VERSION ""

NS_ :

BS_:

BU_: K16_BECM K73_TCIC K9_BCM K43_PSCM K17_EBCM K20_ECM K114B_HPCM NEO K124_ASCM EPB INTERCEPTOR XXX Vector__XXX

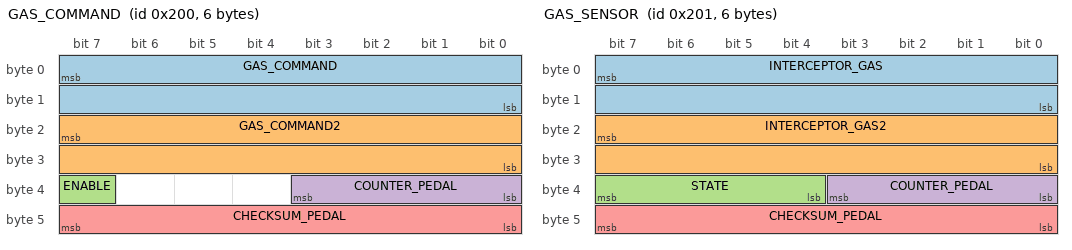
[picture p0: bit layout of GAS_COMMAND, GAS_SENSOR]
BO_ 512 GAS_COMMAND: 6 NEO
 SG_ GAS_COMMAND : 7|16@0+ (0.125677,-75.909) [0|1] "" INTERCEPTOR
 SG_ GAS_COMMAND2 : 23|16@0+ (0.251976,-76.601) [0|1] "" INTERCEPTOR
 SG_ ENABLE : 39|1@0+ (1,0) [0|1] "" INTERCEPTOR
 SG_ COUNTER_PEDAL : 35|4@0+ (1,0) [0|15] "" INTERCEPTOR
 SG_ CHECKSUM_PEDAL : 47|8@0+ (1,0) [0|255] "" INTERCEPTOR

BO_ 513 GAS_SENSOR: 6 INTERCEPTOR
 SG_ INTERCEPTOR_GAS : 7|16@0+ (0.125677,-75.909) [0|1] "" NEO
 SG_ INTERCEPTOR_GAS2 : 23|16@0+ (0.251976,-76.601) [0|1] "" NEO
 SG_ STATE : 39|4@0+ (1,0) [0|15] "" NEO
 SG_ COUNTER_PEDAL : 35|4@0+ (1,0) [0|15] "" NEO
 SG_ CHECKSUM_PEDAL : 47|8@0+ (1,0) [0|255] "" NEO

BO_ 189 EBCMRegenPaddle: 7 K17_EBCM
 SG_ RegenPaddle : 7|4@0+ (1,0) [0|0] "" NEO

BO_ 190 ECMAcceleratorPos: 6 K20_ECM
 SG_ BrakePedalPos : 15|8@0+ (1,0) [0|0] "sticky" NEO
 SG_ GasPedalAndAcc : 23|8@0+ (1,0) [0|0] "" NEO

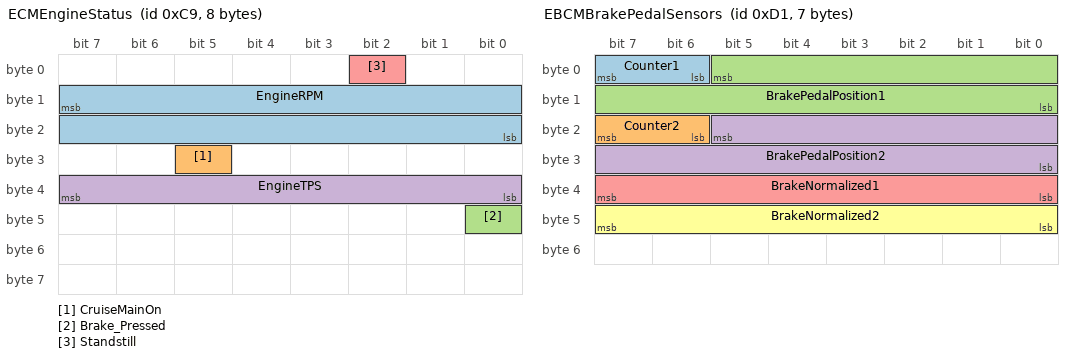
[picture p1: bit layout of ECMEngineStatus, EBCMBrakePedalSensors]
BO_ 201 ECMEngineStatus: 8 K20_ECM
 SG_ EngineRPM : 15|16@0+ (0.25,0) [0|0] "RPM" NEO
 SG_ CruiseMainOn : 29|1@0+ (1,0) [0|1] "" NEO
 SG_ Brake_Pressed : 40|1@0+ (1,0) [0|1] "" NEO
 SG_ EngineTPS : 39|8@0+ (0.392156863,0) [0|100.000000065] "%" NEO
 SG_ Standstill : 2|1@0+ (1,0) [0|1] "" NEO

BO_ 209 EBCMBrakePedalSensors: 7 K17_EBCM
 SG_ Counter1 : 7|2@0+ (1,0) [0|3] "" XXX
 SG_ Counter2 : 23|2@0+ (1,0) [0|3] "" XXX
 SG_ BrakePedalPosition1 : 5|14@0+ (1,0) [0|16383] "" XXX
 SG_ BrakePedalPosition2 : 21|14@0- (-1,0) [0|16383] "" XXX
 SG_ BrakeNormalized1 : 39|8@0+ (1,0) [0|255] "" XXX
 SG_ BrakeNormalized2 : 47|8@0- (-1,0) [0|255] "" XXX

BO_ 241 EBCMBrakePedalPosition: 6 K17_EBCM
 SG_ BrakePedalPosition : 15|8@0+ (1,0) [0|255] "" NEO

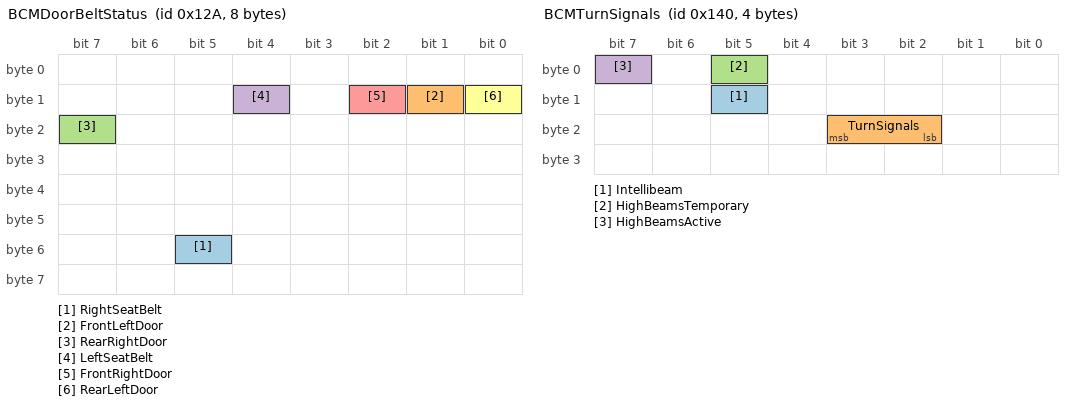
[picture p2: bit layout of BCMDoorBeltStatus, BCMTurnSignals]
BO_ 298 BCMDoorBeltStatus: 8 K9_BCM
 SG_ RightSeatBelt : 53|1@0+ (1,0) [0|0] "" NEO
 SG_ FrontLeftDoor : 9|1@0+ (1,0) [0|0] "" NEO
 SG_ RearRightDoor : 23|1@0+ (1,0) [0|0] "" NEO
 SG_ LeftSeatBelt : 12|1@0+ (1,0) [0|0] "" NEO
 SG_ FrontRightDoor : 10|1@0+ (1,0) [0|0] "" NEO
 SG_ RearLeftDoor : 8|1@0+ (1,0) [0|0] "" NEO

BO_ 309 ECMPRDNL: 8 K20_ECM
 SG_ PRNDL : 2|3@0+ (1,0) [0|0] "" NEO
 SG_ ESPButton : 4|1@0+ (1,0) [0|1] "" XXX

BO_ 320 BCMTurnSignals: 4 K9_BCM
 SG_ Intellibeam : 13|1@0+ (1,0) [0|1] "" XXX
 SG_ TurnSignals : 19|2@0+ (1,0) [0|0] "" NEO
 SG_ HighBeamsTemporary : 5|1@0+ (1,0) [0|1] "" XXX
 SG_ HighBeamsActive : 7|1@0+ (1,0) [0|1] "" XXX

BO_ 328 PSCM_148: 1 K43_PSCM

BO_ 381 ESPStatus: 8 K20_ECM
 SG_ TractionControlOn : 5|1@0+ (1,0) [0|0] "" NEO
 SG_ MSG17D_AccPower : 35|12@0- (1,0) [0|0] "" NEO

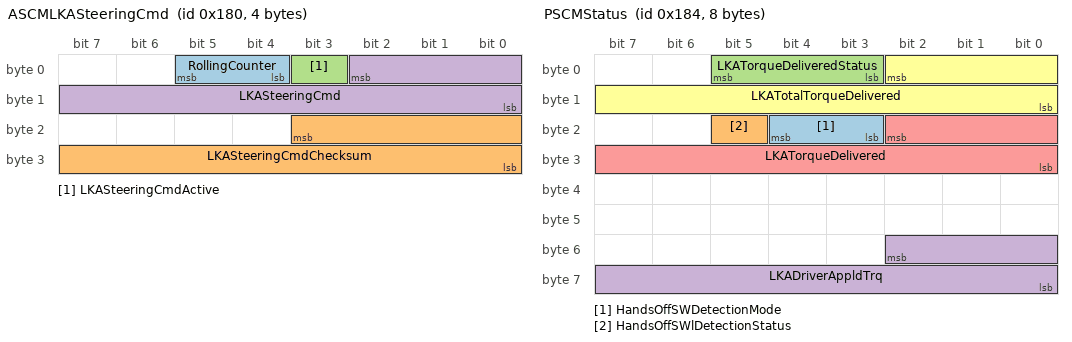
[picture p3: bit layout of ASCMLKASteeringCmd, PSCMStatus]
BO_ 384 ASCMLKASteeringCmd: 4 NEO
 SG_ RollingCounter : 5|2@0+ (1,0) [0|0] "" NEO
 SG_ LKASteeringCmdChecksum : 19|12@0+ (1,0) [0|0] "" NEO
 SG_ LKASteeringCmdActive : 3|1@0+ (1,0) [0|0] "" NEO
 SG_ LKASteeringCmd : 2|11@0- (1,0) [0|0] "" NEO

BO_ 388 PSCMStatus: 8 K43_PSCM
 SG_ HandsOffSWDetectionMode : 20|2@0+ (1,0) [0|3] "" NEO
 SG_ HandsOffSWlDetectionStatus : 21|1@0+ (1,0) [0|1] "" NEO
 SG_ LKATorqueDeliveredStatus : 5|3@0+ (1,0) [0|7] "" NEO
 SG_ LKADriverAppldTrq : 50|11@0- (0.01,0) [-10.24|10.23] "Nm" NEO
 SG_ LKATorqueDelivered : 18|11@0- (0.01,0) [0|1] "" NEO
 SG_ LKATotalTorqueDelivered : 2|11@0- (0.01,0) [-10.24|10.23] "Nm" NEO

BO_ 417 AcceleratorPedal: 7 XXX
 SG_ AcceleratorPedal : 55|8@0+ (1,0) [0|0] "" NEO

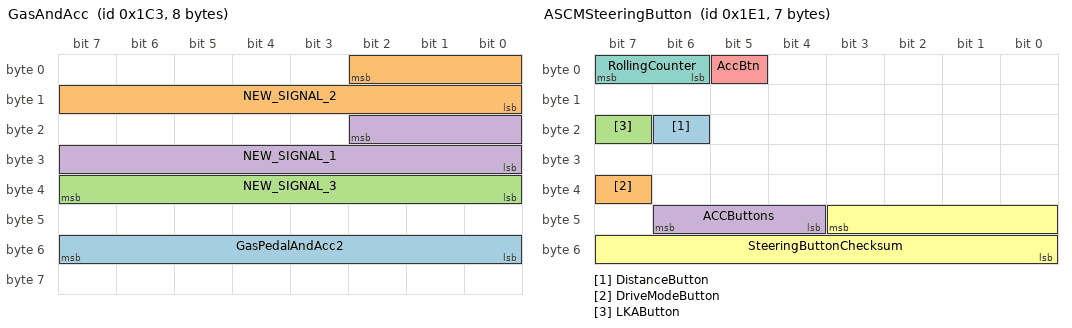
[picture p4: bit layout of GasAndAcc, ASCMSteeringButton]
BO_ 451 GasAndAcc: 8 XXX
 SG_ GasPedalAndAcc2 : 55|8@0+ (1,0) [0|0] "" NEO
 SG_ NEW_SIGNAL_2 : 2|11@0+ (1,0) [0|2047] "" XXX
 SG_ NEW_SIGNAL_3 : 32|8@1+ (1,0) [0|255] "" XXX
 SG_ NEW_SIGNAL_1 : 18|11@0+ (1,0) [0|2047] "" XXX

BO_ 452 AcceleratorPedal2: 8 XXX
 SG_ CruiseState : 15|3@0+ (1,0) [0|7] "" NEO
 SG_ AcceleratorPedal2 : 47|8@0+ (1,0) [0|0] "" NEO

BO_ 481 ASCMSteeringButton: 7 K124_ASCM
 SG_ DistanceButton : 22|1@0+ (1,0) [0|0] "" NEO
 SG_ DriveModeButton : 39|1@0+ (1,0) [0|1] "" XXX
 SG_ LKAButton : 23|1@0+ (1,0) [0|0] "" NEO
 SG_ ACCButtons : 46|3@0+ (1,0) [0|0] "" NEO
 SG_ AccBtn : 5|1@0+ (1,0) [0|1] "" XXX
 SG_ SteeringButtonChecksum : 43|12@0+ (1,0) [0|255] "" NEO
 SG_ RollingCounter : 7|2@0+ (1,0) [0|3] "" NEO

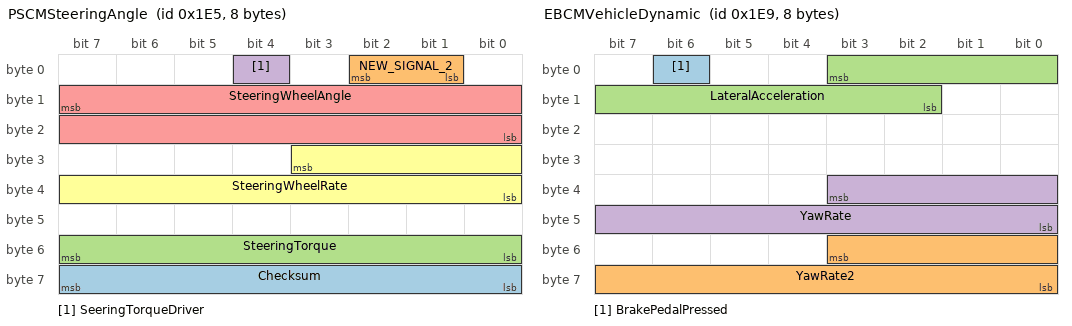
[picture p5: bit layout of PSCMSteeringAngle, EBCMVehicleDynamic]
BO_ 485 PSCMSteeringAngle: 8 K43_PSCM
 SG_ Checksum : 56|8@1+ (1,0) [0|255] "" XXX
 SG_ NEW_SIGNAL_2 : 1|2@1+ (1,0) [0|255] "" XXX
 SG_ SteeringTorque : 48|8@1- (1,0) [-2047|2047] "" XXX
 SG_ SeeringTorqueDriver : 4|1@1- (1,0) [-255|255] "" XXX
 SG_ SteeringWheelAngle : 15|16@0- (0.0625,0) [-2047|2047] "deg" NEO
 SG_ SteeringWheelRate : 27|12@0- (1,0) [-2047|2047] "deg/s" NEO

BO_ 489 EBCMVehicleDynamic: 8 K17_EBCM
 SG_ BrakePedalPressed : 6|1@0+ (1,0) [0|0] "" NEO
 SG_ YawRate2 : 51|12@0- (0.0625,0) [-2047|2047] "grad/s" NEO
 SG_ LateralAcceleration : 3|10@0- (1,0) [-2047|2047] "m/s2" NEO
 SG_ YawRate : 35|12@0- (1,0) [0|1] "" NEO

BO_ 352 VehicleIgnition: 5 XXX
 SG_ Ignition : 7|32@0+ (1,0) [0|4294967295] "" XXX

BO_ 497 VehicleIgnitionAlt: 8 XXX
 SG_ Ignition : 5|1@0+ (1,0) [0|1] "" XXX
 SG_ ParkBrake : 36|1@0+ (1,0) [0|3] "" XXX

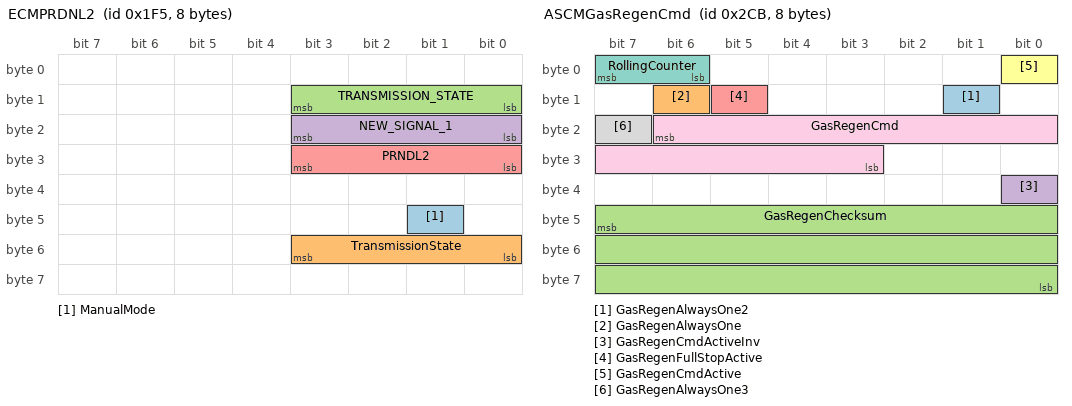
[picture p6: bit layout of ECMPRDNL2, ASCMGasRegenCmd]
BO_ 501 ECMPRDNL2: 8 K20_ECM
 SG_ ManualMode : 41|1@0+ (1,0) [0|1] "" NEO
 SG_ TransmissionState : 48|4@1+ (1,0) [0|7] "" NEO
 SG_ TRANSMISSION_STATE : 8|4@1+ (1,0) [0|15] "" XXX
 SG_ NEW_SIGNAL_1 : 16|4@1+ (1,0) [0|15] "" XXX
 SG_ PRNDL2 : 27|4@0+ (1,0) [0|255] "" NEO

BO_ 560 EPBStatus: 8 EPB
 SG_ EPBClosed : 12|1@0+ (1,0) [0|1] "" NEO

BO_ 711 BECMBatteryVoltageCurrent: 6 K17_EBCM
 SG_ HVBatteryVoltage : 31|12@0+ (0.125,0) [0|511.875] "V" NEO
 SG_ HVBatteryCurrent : 12|13@0- (0.15,0) [-614.4|614.25] "A" NEO

BO_ 715 ASCMGasRegenCmd: 8 K124_ASCM
 SG_ GasRegenAlwaysOne2 : 9|1@0+ (1,0) [0|1] "" NEO
 SG_ GasRegenAlwaysOne : 14|1@0+ (1,0) [0|1] "" NEO
 SG_ GasRegenChecksum : 47|24@0+ (1,0) [0|0] "" NEO
 SG_ GasRegenCmdActiveInv : 32|1@0+ (1,0) [0|0] "" NEO
 SG_ GasRegenFullStopActive : 13|1@0+ (1,0) [0|0] "" NEO
 SG_ GasRegenCmdActive : 0|1@0+ (1,0) [0|0] "" NEO
 SG_ RollingCounter : 7|2@0+ (1,0) [0|0] "" NEO
 SG_ GasRegenAlwaysOne3 : 23|1@0+ (1,0) [0|1] "" NEO
 SG_ GasRegenCmd : 22|12@0+ (1,0) [0|0] "" NEO

BO_ 717 ASCM_2CD: 5 K124_ASCM

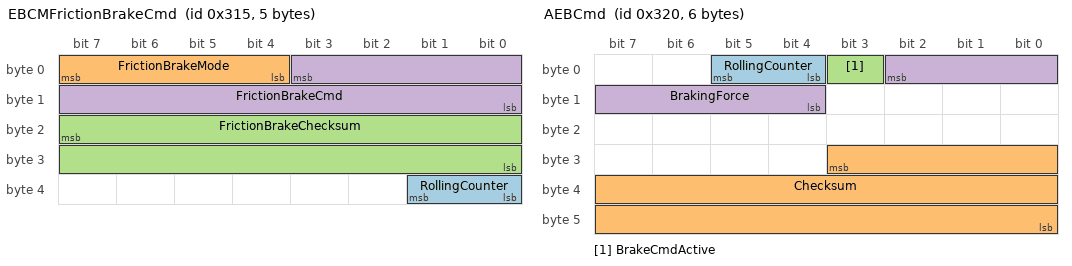
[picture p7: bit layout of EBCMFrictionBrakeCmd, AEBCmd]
BO_ 789 EBCMFrictionBrakeCmd: 5 K124_ASCM
 SG_ RollingCounter : 33|2@0+ (1,0) [0|0] "" NEO
 SG_ FrictionBrakeMode : 7|4@0+ (1,0) [0|0] "" NEO
 SG_ FrictionBrakeChecksum : 23|16@0+ (1,0) [0|0] "" NEO
 SG_ FrictionBrakeCmd : 3|12@0- (1,0) [0|0] "" NEO

BO_ 800 AEBCmd: 6 K124_ASCM
 SG_ RollingCounter : 5|2@0+ (1,0) [0|3] "" NEO
 SG_ Checksum : 27|20@0+ (1,0) [0|2047] "" NEO
 SG_ BrakeCmdActive : 3|1@1+ (1,0) [0|1] "" NEO
 SG_ BrakingForce : 2|7@0+ (1,0) [0|7] "" NEO

BO_ 810 TCICOnStarGPSPosition: 8 K73_TCIC
 SG_ GPSLongitude : 39|32@0+ (1,-2147483648) [0|0] "milliarcsecond" NEO
 SG_ GPSLatitude : 7|32@0+ (1,0) [0|0] "milliarcsecond" NEO

BO_ 840 EBCMWheelSpdFront: 6 K17_EBCM
 SG_ FLWheelSpd : 7|16@0+ (0.0311,0) [0|255] "km/h" NEO
 SG_ FRWheelSpd : 22|15@0+ (0.0647,0) [0|255] "km/h" XXX

BO_ 842 EBCMWheelSpdRear: 6 K17_EBCM
 SG_ RLWheelSpd : 7|16@0+ (0.0311,0) [0|255] "km/h" NEO
 SG_ RRWheelSpd : 22|15@0+ (0.0647,0) [0|255] "km/h" XXX

BO_ 869 ASCM_365: 4 K124_ASCM

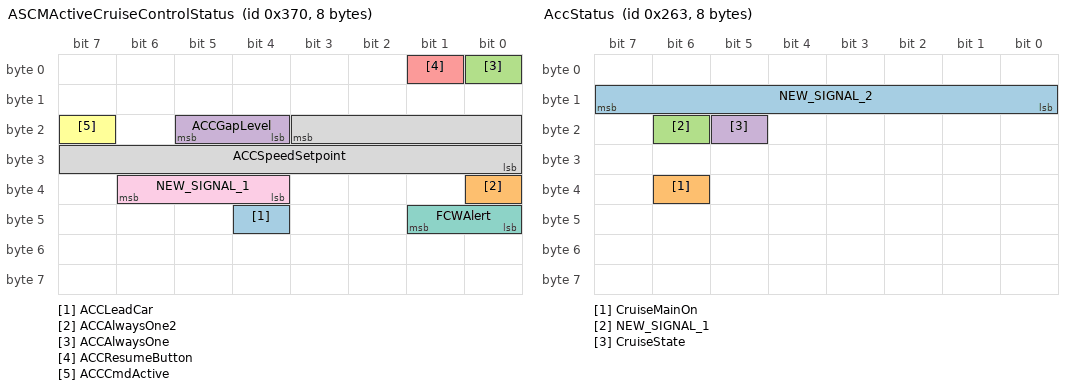
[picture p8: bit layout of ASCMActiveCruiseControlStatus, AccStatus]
BO_ 880 ASCMActiveCruiseControlStatus: 8 K124_ASCM
 SG_ ACCLeadCar : 44|1@0+ (1,0) [0|0] "" Vector__XXX
 SG_ ACCAlwaysOne2 : 32|1@0+ (1,0) [0|0] "" Vector__XXX
 SG_ ACCAlwaysOne : 0|1@0+ (1,0) [0|0] "" Vector__XXX
 SG_ ACCGapLevel : 21|2@0+ (1,0) [0|0] "" NEO
 SG_ ACCResumeButton : 1|1@0+ (1,0) [0|0] "" NEO
 SG_ ACCCmdActive : 23|1@0+ (1,0) [0|0] "" NEO
 SG_ FCWAlert : 41|2@0+ (1,0) [0|3] "" XXX
 SG_ ACCSpeedSetpoint : 19|12@0+ (1,0) [0|0] "km/h" NEO
 SG_ NEW_SIGNAL_1 : 38|3@0+ (1,0) [0|7] "" XXX

BO_ 1001 ECMVehicleSpeed: 8 K20_ECM
 SG_ VehicleSpeed : 7|16@0+ (0.01,0) [0|0] "mph" NEO

BO_ 1033 ASCMKeepAlive: 7 NEO
 SG_ ASCMKeepAliveAllZero : 7|56@0+ (1,0) [0|0] "" NEO

BO_ 1034 ASCM_40A: 7 K124_ASCM

BO_ 1217 ECMEngineCoolantTemp: 8 K20_ECM
 SG_ EngineCoolantTemp : 23|8@0+ (1,-40) [0|0] "C" NEO
 SG_ NEW_SIGNAL_1 : 7|16@0- (1,0) [0|65535] "" XXX

BO_ 1249 VIN_Part2: 8 K20_ECM
 SG_ VINPart2 : 7|64@0+ (1,0) [0|0] "" NEO

BO_ 1296 ASCM_510: 4 K124_ASCM

BO_ 1300 VIN_Part1: 8 K20_ECM
 SG_ VINPart1 : 7|64@0+ (1,0) [0|0] "" NEO

BO_ 1912 PSCM_778: 8 K43_PSCM

BO_ 1930 ASCM_78A: 7 K124_ASCM

BO_ 611 AccStatus: 8 XXX
 SG_ NEW_SIGNAL_2 : 8|8@1+ (1,0) [0|255] "" XXX
 SG_ CruiseMainOn : 38|1@0+ (1,0) [0|1] "" XXX
 SG_ NEW_SIGNAL_1 : 22|1@0+ (1,0) [0|1] "" XXX
 SG_ CruiseState : 21|1@0+ (1,0) [0|1] "" XXX

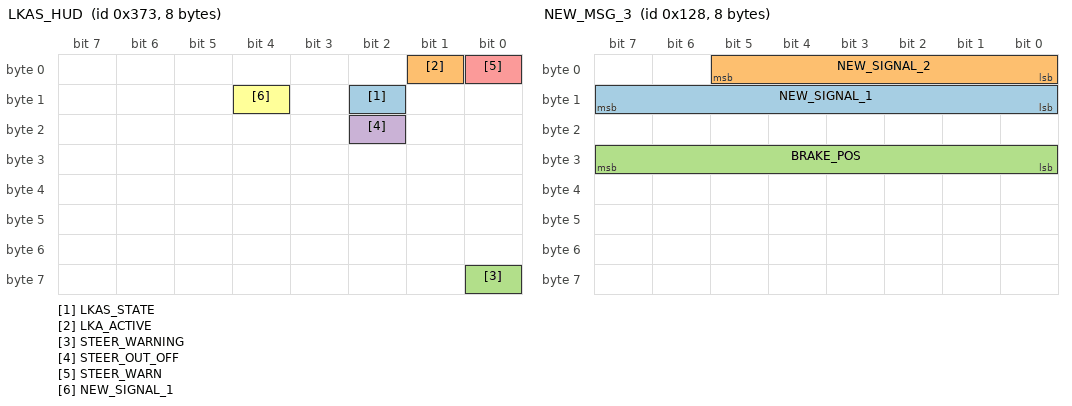
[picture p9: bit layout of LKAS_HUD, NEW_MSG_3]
BO_ 883 LKAS_HUD: 8 XXX
 SG_ LKAS_STATE : 10|1@0+ (1,0) [0|1] "" XXX
 SG_ LKA_ACTIVE : 1|1@0+ (1,0) [0|1] "" XXX
 SG_ STEER_WARNING : 56|1@0+ (1,0) [0|1] "" XXX
 SG_ STEER_OUT_OFF : 18|1@0+ (1,0) [0|1] "" XXX
 SG_ STEER_WARN : 0|1@0+ (1,0) [0|1] "" XXX
 SG_ NEW_SIGNAL_1 : 12|1@0+ (1,0) [0|1] "" XXX

BO_ 296 NEW_MSG_3: 8 XXX
 SG_ NEW_SIGNAL_1 : 15|8@0+ (1,0) [0|255] "" XXX
 SG_ NEW_SIGNAL_2 : 0|6@1+ (1,0) [0|255] "" XXX
 SG_ BRAKE_POS : 24|8@1- (1,0) [-255|255] "" XXX

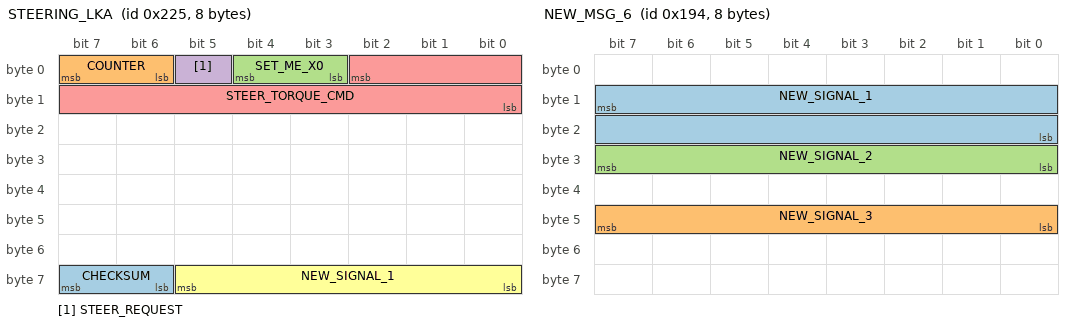
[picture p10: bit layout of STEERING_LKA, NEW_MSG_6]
BO_ 549 STEERING_LKA: 8 XXX
 SG_ CHECKSUM : 62|2@1+ (1,0) [0|255] "" XXX
 SG_ COUNTER : 7|2@0+ (1,0) [0|3] "" XXX
 SG_ SET_ME_X0 : 3|2@1+ (1,0) [0|3] "" XXX
 SG_ STEER_REQUEST : 5|1@0+ (1,0) [0|1] "" XXX
 SG_ STEER_TORQUE_CMD : 2|11@0- (1,0) [0|2047] "" XXX
 SG_ NEW_SIGNAL_1 : 56|6@1+ (1,0) [0|63] "" XXX

BO_ 1047 NEW_MSG_5: 8 XXX

BO_ 404 NEW_MSG_6: 8 XXX
 SG_ NEW_SIGNAL_1 : 15|16@0- (1,-1024) [0|65535] "" XXX
 SG_ NEW_SIGNAL_3 : 40|8@1+ (1,0) [0|255] "" XXX
 SG_ NEW_SIGNAL_2 : 24|8@1+ (1,0) [-255|255] "" XXX

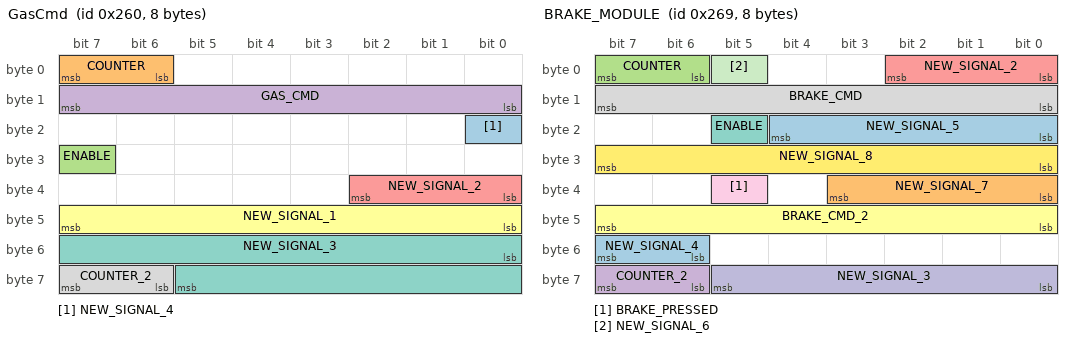
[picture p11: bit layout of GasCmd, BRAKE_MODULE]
BO_ 608 GasCmd: 8 XXX
 SG_ NEW_SIGNAL_4 : 16|1@0+ (1,0) [0|1] "" XXX
 SG_ COUNTER : 7|2@0+ (1,0) [0|3] "" XXX
 SG_ ENABLE : 31|1@0+ (1,0) [0|1] "" XXX
 SG_ GAS_CMD : 8|8@1- (1,0) [0|255] "" XXX
 SG_ NEW_SIGNAL_2 : 32|3@1+ (1,0) [0|7] "" XXX
 SG_ NEW_SIGNAL_1 : 47|8@0+ (1,0) [0|65535] "" XXX
 SG_ NEW_SIGNAL_3 : 48|14@1+ (1,0) [0|4095] "" XXX
 SG_ COUNTER_2 : 63|2@0+ (1,0) [0|3] "" XXX

BO_ 996 NEW_MSG_8: 8 XXX

BO_ 617 BRAKE_MODULE: 8 XXX
 SG_ NEW_SIGNAL_4 : 55|2@0+ (1,0) [0|3] "" XXX
 SG_ NEW_SIGNAL_7 : 32|4@1+ (1,0) [0|15] "" XXX
 SG_ COUNTER : 7|2@0+ (1,0) [0|3] "" XXX
 SG_ COUNTER_2 : 63|2@0+ (1,0) [0|3] "" XXX
 SG_ NEW_SIGNAL_2 : 0|3@1+ (1,0) [0|7] "" XXX
 SG_ BRAKE_CMD_2 : 40|8@1+ (1,0) [0|255] "" XXX
 SG_ ENABLE : 21|1@0+ (1,0) [0|1] "" XXX
 SG_ BRAKE_CMD : 15|8@0+ (1,0) [0|2047] "" XXX
 SG_ BRAKE_PRESSED : 37|1@0+ (1,0) [0|1] "" XXX
 SG_ NEW_SIGNAL_3 : 56|6@1+ (1,0) [0|63] "" XXX
 SG_ NEW_SIGNAL_6 : 5|1@0+ (1,0) [0|1] "" XXX
 SG_ NEW_SIGNAL_8 : 24|8@1+ (1,0) [0|255] "" XXX
 SG_ NEW_SIGNAL_5 : 16|5@1+ (1,0) [0|31] "" XXX

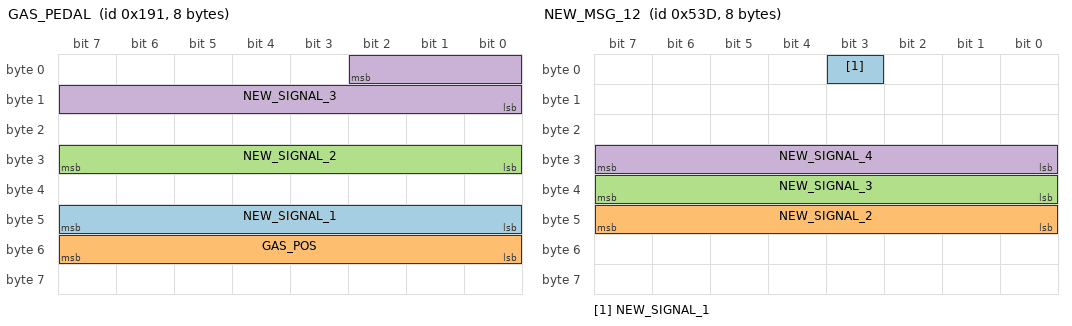
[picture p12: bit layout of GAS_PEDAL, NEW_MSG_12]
BO_ 401 GAS_PEDAL: 8 XXX
 SG_ NEW_SIGNAL_1 : 40|8@1+ (1,0) [0|255] "" XXX
 SG_ GAS_POS : 48|8@1+ (1,0) [0|255] "" XXX
 SG_ NEW_SIGNAL_2 : 31|8@0+ (1,0) [0|255] "" XXX
 SG_ NEW_SIGNAL_3 : 2|11@0+ (1,0) [0|2047] "" XXX

BO_ 1065 NEW_MSG_4: 8 XXX
 SG_ LKA_STATE : 15|1@0+ (1,0) [0|1] "" XXX

BO_ 1041 NEW_MSG_11: 8 XXX

BO_ 1341 NEW_MSG_12: 8 XXX
 SG_ NEW_SIGNAL_1 : 3|1@0+ (1,0) [0|1] "" XXX
 SG_ NEW_SIGNAL_2 : 40|8@1+ (1,0) [0|255] "" XXX
 SG_ NEW_SIGNAL_3 : 32|8@1+ (1,0) [0|255] "" XXX
 SG_ NEW_SIGNAL_4 : 24|8@1+ (1,0) [0|255] "" XXX

BO_ 225 BCMDoorBelt: 8 XXX
 SG_ LEFTSEATBEALT : 23|1@0+ (1,0) [0|1] "" XXX
 SG_ RIGHTSEATBEALT : 11|1@0+ (1,0) [0|1] "" XXX

BO_ 844 NEW_MSG_7: 8 XXX
 SG_ NEW_SIGNAL_1 : 15|16@0+ (1,0) [0|65535] "" XXX
 SG_ NEW_SIGNAL_2 : 31|16@0+ (1,0) [0|65535] "" XXX

BO_ 846 NEW_MSG_9: 8 XXX
 SG_ NEW_SIGNAL_2 : 15|8@0- (1,0) [0|255] "" XXX

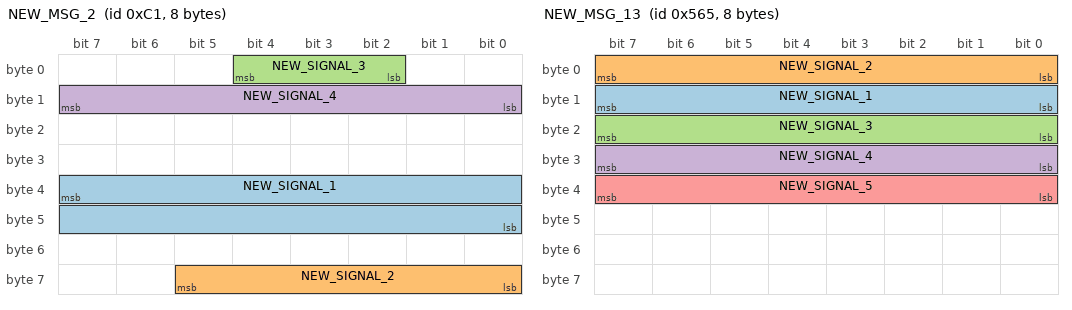
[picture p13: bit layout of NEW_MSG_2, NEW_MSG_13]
BO_ 193 NEW_MSG_2: 8 XXX
 SG_ NEW_SIGNAL_1 : 39|16@0+ (1,0) [0|65535] "" XXX
 SG_ NEW_SIGNAL_2 : 56|6@1+ (1,0) [0|63] "" XXX
 SG_ NEW_SIGNAL_3 : 4|3@0+ (1,0) [0|7] "" XXX
 SG_ NEW_SIGNAL_4 : 8|8@1+ (1,0) [0|255] "" XXX

BO_ 1381 NEW_MSG_13: 8 XXX
 SG_ NEW_SIGNAL_1 : 8|8@1+ (1,0) [0|255] "" XXX
 SG_ NEW_SIGNAL_2 : 0|8@1+ (1,0) [0|255] "" XXX
 SG_ NEW_SIGNAL_3 : 16|8@1+ (1,0) [0|255] "" XXX
 SG_ NEW_SIGNAL_4 : 24|8@1+ (1,0) [0|255] "" XXX
 SG_ NEW_SIGNAL_5 : 32|8@1+ (1,0) [0|255] "" XXX

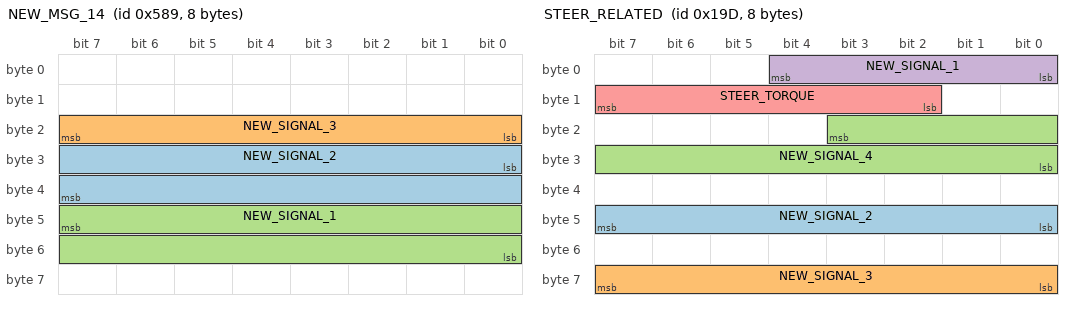
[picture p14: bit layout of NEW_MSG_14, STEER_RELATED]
BO_ 1417 NEW_MSG_14: 8 XXX
 SG_ NEW_SIGNAL_2 : 24|16@1- (1,0) [0|65535] "" XXX
 SG_ NEW_SIGNAL_3 : 16|8@1+ (1,0) [0|255] "" XXX
 SG_ NEW_SIGNAL_1 : 47|16@0+ (0.01,0) [0|65535] "" XXX

BO_ 413 STEER_RELATED: 8 XXX
 SG_ NEW_SIGNAL_2 : 47|8@0+ (1,0) [0|65535] "" XXX
 SG_ NEW_SIGNAL_3 : 56|8@1+ (1,0) [0|255] "" XXX
 SG_ NEW_SIGNAL_4 : 19|12@0+ (1,0) [0|4095] "" XXX
 SG_ NEW_SIGNAL_1 : 0|5@1+ (1,0) [0|31] "" XXX
 SG_ STEER_TORQUE : 15|6@0- (1,0) [-255|255] "" XXX

BO_ 454 NEW_MSG_15: 8 XXX
 SG_ NEW_SIGNAL_1 : 0|5@1+ (1,0) [0|31] "" XXX

BO_ 997 NEW_MSG_16: 8 XXX
 SG_ NEW_SIGNAL_1 : 8|8@1- (1,0) [0|255] "" XXX

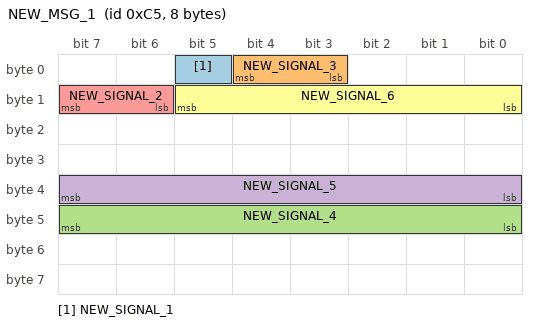
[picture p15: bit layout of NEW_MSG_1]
BO_ 197 NEW_MSG_1: 8 XXX
 SG_ NEW_SIGNAL_1 : 5|1@0+ (1,0) [0|1] "" XXX
 SG_ NEW_SIGNAL_3 : 3|2@1+ (1,0) [0|3] "" XXX
 SG_ NEW_SIGNAL_4 : 40|8@1+ (1,0) [0|255] "" XXX
 SG_ NEW_SIGNAL_5 : 32|8@1+ (1,0) [0|255] "" XXX
 SG_ NEW_SIGNAL_2 : 14|2@1+ (1,0) [0|3] "" XXX
 SG_ NEW_SIGNAL_6 : 8|6@1+ (1,0) [0|63] "" XXX

BO_ 848 NEW_MSG_10: 8 XXX
 SG_ NEW_SIGNAL_1 : 8|8@1+ (1,0) [0|255] "" XXX
 SG_ NEW_SIGNAL_2 : 0|8@1+ (1,0) [0|255] "" XXX

BO_TX_BU_ 384 : K124_ASCM,NEO;
BO_TX_BU_ 715 : NEO,K124_ASCM;
BO_TX_BU_ 789 : NEO,K124_ASCM;
BO_TX_BU_ 800 : NEO,K124_ASCM;
BO_TX_BU_ 880 : NEO,K124_ASCM;
BO_TX_BU_ 1033 : K124_ASCM,NEO;

CM_ BU_ K16_BECM "Battery Energy Control Module";
CM_ BU_ K73_TCIC "Telematics Communication Control Module";
CM_ BU_ K9_BCM "Body Control Module";
CM_ BU_ K43_PSCM "Power Steering Control Module";
CM_ BU_ K17_EBCM "Electronic Brake Control Module";
CM_ BU_ K20_ECM "Engine Control Module";
CM_ BU_ K114B_HPCM "Hybrid Powertrain Control Module";
CM_ BU_ NEO "Comma NEO";
CM_ BU_ K124_ASCM "Active Safety Control Module";CM_ SG_ 190 GasPedalAndAcc "ACC baseline is 62";CM_ SG_ 381 MSG17D_AccPower "Need to investigate";CM_ SG_ 451 GasPedalAndAcc2 "ACC baseline is 62";CM_ SG_ 352 Ignition "Non-zero when ignition is on";CM_ SG_ 497 Ignition "Describes ignition + preconditioning mode, noisy";CM_ SG_ 501 PRNDL2 "When ManualMode is Active, Value is 13=L1 12=L2 11=L3 ... 4=L10";
VAL_ 513 STATE 5 "FAULT_TIMEOUT" 4 "FAULT_STARTUP" 3 "FAULT_SCE" 2 "FAULT_SEND" 1 "FAULT_BAD_CHECKSUM" 0 "NO_FAULT" ;
VAL_ 309 PRNDL 3 "R" 2 "D" 1 "N" 0 "P" ;
VAL_ 309 ESPButton 1 "Active" 0 "Inactive" ;
VAL_ 320 Intellibeam 1 "Active" 0 "Inactive" ;
VAL_ 320 HighBeamsTemporary 1 "Active" 0 "Inactive" ;
VAL_ 384 LKASteeringCmdActive 1 "Active" 0 "Inactive" ;
VAL_ 388 HandsOffSWDetectionMode 2 "Failed" 1 "Enabled" 0 "Disabled" ;
VAL_ 388 HandsOffSWlDetectionStatus 1 "Hands On" 0 "Hands Off" ;
VAL_ 388 LKATorqueDeliveredStatus 3 "Failed" 2 "Temp. Limited" 1 "Active" 0 "Inactive" ;
VAL_ 452 CruiseState 4 "Standstill" 3 "Faulted" 1 "Active" 0 "Off" ;
VAL_ 481 DistanceButton 1 "Active" 0 "Inactive" ;
VAL_ 481 DriveModeButton 1 "Active" 0 "Inactive" ;
VAL_ 481 LKAButton 1 "Active" 0 "Inactive" ;
VAL_ 481 ACCButtons 6 "Cancel" 5 "Main" 3 "Set" 2 "Resume" 1 "None" ;
VAL_ 489 BrakePedalPressed 1 "Pressed" 0 "Depressed" ;
VAL_ 501 TransmissionState 11 "Shifting" 10 "Reverse" 9 "Forward" 8 "Disengaged" ;
VAL_ 501 PRNDL2 6 "L" 4 "D" 3 "N" 2 "R" 1 "P" 0 "Shifting" ;
VAL_ 715 GasRegenCmdActiveInv 1 "Inactive" 0 "Active" ;
VAL_ 715 GasRegenCmdActive 1 "Active" 0 "Inactive" ;
VAL_ 880 ACCLeadCar 1 "Present" 0 "Not Present" ;
VAL_ 880 ACCGapLevel 3 "Far" 2 "Med" 1 "Near" 0 "Inactive" ;
VAL_ 880 ACCResumeButton 1 "Pressed" 0 "Depressed" ;
VAL_ 880 ACCCmdActive 1 "Active" 0 "Inactive" ;
CM_ "AUTOGENERATED FILE, DO NOT EDIT";
CM_ "Imported file _comma.dbc starts here";
CM_ "gm_global_a_powertrain.dbc starts here";
